# NM1120AE_v1 register map
File version: 1.0
Registers are 32-bit, read-write, reset 0x0 unless marked. A register's access mark holds for its fields unless they carry their own. Offsets are from the block's base; [hi:lo] are bit positions.

## SYS — SYS Register Map
Base 0x50000000
0x00 SYS_PDID ro reset not defined — Part Device Identification Number Register
  [31:0] PDID — Part Device Identification Number (Read Only). This register reflects device part number code. Software can read this register to identify which device is used.
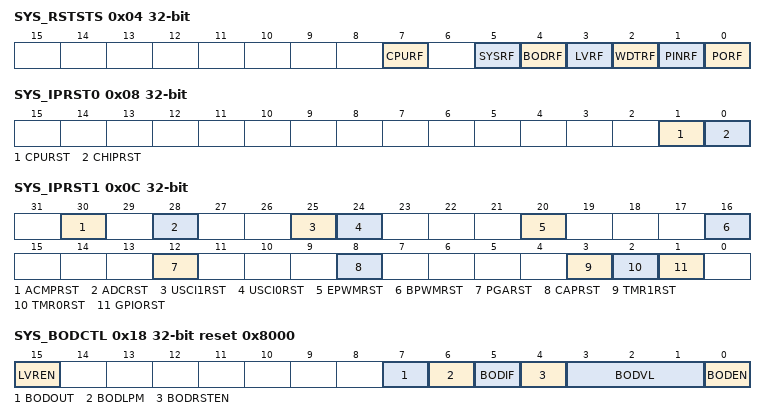
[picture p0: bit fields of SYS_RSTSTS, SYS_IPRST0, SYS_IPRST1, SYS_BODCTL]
0x04 SYS_RSTSTS (reset mask 0xFFFFFF00) — System Reset Status Register
  [7] CPURF — CPU Reset Flag. The CPU reset flag is set by hardware if software writes CPURST (SYS_IPRST0[1]) 1 to reset Cortex-M0 Core and Flash Memory Controller (FMC). Note: Write 1 to clear this bit to 0.
    0=No reset from CPU; 1=The Cortex-M0 Core and FMC are reset by software setting CPURST to 1
  [5] SYSRF — System Reset Flag. The system reset flag is set by the "Reset Signal" from the Cortex-M0 Core to indicate the previous reset source. Note: Write 1 to clear this bit to 0.
    0=No reset from Cortex-M0; 1=The Cortex-M0 had issued the reset signal to reset the system by writing 1 to the bit SYSRESETREQ(AIRCR[2], Application Interrupt and Reset Control Register, address = 0xE000ED0C) in system control registers of Cortex-M0 core
  [4] BODRF — BOD Reset Flag. The BOD reset flag is set by the "Reset Signal" from the Brown-Out Detector to indicate the previous reset source. Note: Write 1 to clear this bit to 0.
    0=No reset from BOD; 1=The BOD had issued the reset signal to reset the system
  [3] LVRF — LVR Reset Flag. The LVR reset flag is set by the "Reset Signal" from the Low Voltage Reset Controller to indicate the previous reset source. Note: Write 1 to clear this bit to 0.
    0=No reset from LVR; 1=LVR controller had issued the reset signal to reset the system
  [2] WDTRF — WDT Reset Flag. The WDT reset flag is set by the "Reset Signal" from the Watchdog Timer or Window Watchdog Timer to indicate the previous reset source. Note1: Write 1 to clear this bit to 0. Note2: Watchdog Timer register RSTF(WDT_CTL[2]) bit is set if the system has been reset by WDT time-out reset. Window Watchdog Timer register WWDTRF(WWDT_STATUS[1]) bit is set if the system has been reset by WWDT time-out reset.
    0=No reset from watchdog timer or window watchdog timer; 1=The watchdog timer or window watchdog timer had issued the reset signal to reset the system
  [1] PINRF — NRESET Pin Reset Flag. The nRESET pin reset flag is set by the "Reset Signal" from the nRESET Pin to indicate the previous reset source. Note: Write 1 to clear this bit to 0.
    0=No reset from nRESET pin; 1=Pin nRESET had issued the reset signal to reset the system
  [0] PORF — POR Reset Flag. The POR reset flag is set by the "Reset Signal" from the Power-on Reset (POR) Controller or bit CHIPRST (SYS_IPRST0[0]) to indicate the previous reset source. Note: Write 1 to clear this bit to 0.
    0=No reset from POR or CHIPRST; 1=Power-on Reset (POR) or CHIPRST had issued the reset signal to reset the system
0x08 SYS_IPRST0 — Peripheral Reset Control Register 0
  [1] CPURST — Processor Core One-shot Reset (Write Protect). Setting this bit will only reset the processor core and Flash Memory Controller(FMC), and this bit will automatically return to 0 after the 2 clock cycles. Note: This bit is write protected. Refer to the SYS_REGLCTL register.
    0=Processor core normal operation; 1=Processor core one-shot reset
  [0] CHIPRST — Chip One-shot Reset (Write Protect). Setting this bit will reset the whole chip, including Processor core and all peripherals, and this bit will automatically return to 0 after the 2 clock cycles. The CHIPRST is same as the POR reset, all the chip controllers is reset and the chip setting from flash are also reload. About the difference between CHIPRST and SYSRESETREQ(AIRCR[2]), please refer to section 6.2.2. Note: This bit is write protected. Refer to the SYS_REGLCTL register.
    0=Chip normal operation; 1=Chip one-shot reset
0x0C SYS_IPRST1 — Peripheral Reset Control Register 1
  [30] ACMPRST — ACMP Controller Reset
    0=ACMP controller normal operation; 1=ACMP controller reset
  [28] ADCRST — ADC Controller Reset
    0=ADC controller normal operation; 1=ADC controller reset
  [25] USCI1RST — USCI1 Controller Reset
    0=USCI1 controller normal operation; 1=USCI1 controller reset
  [24] USCI0RST — USCI0 Controller Reset
    0=USCI0 controller normal operation; 1=USCI0 controller reset
  [20] EPWMRST — Enhanced PWM Controller Reset
    0=EPWM controller normal operation; 1=EPWM controller reset
  [16] BPWMRST — Basic PWM Controller Reset
    0=BPWM controller normal operation; 1=BPWM controller reset
  [12] PGARST — PGA Controller Reset
    0=PGA controller normal operation; 1=PGA controller reset
  [8] CAPRST — CAP Controller Reset
    0=CAP controller normal operation; 1=CAP controller reset
  [3] TMR1RST — Timer1 Controller Reset
    0=Timer1 controller normal operation; 1=Timer1 controller reset
  [2] TMR0RST — Timer0 Controller Reset
    0=Timer0 controller normal operation; 1=Timer0 controller reset
  [1] GPIORST — GPIO Controller Reset
    0=GPIO controller normal operation; 1=GPIO controller reset
0x10 SYS_WAIT reset 0x1 — HCLK Wait State Cycle Control Register
  [0] HCLKWS — HCLK Wait State Cycle Control Bit. This bit is used to enable/disable HCLK wait state when access Flash. Note: When HCLK frequency is faster than 48MHz, insert one wait state is necessary.
    0=No wait state; 1=One wait state inserted when CPU access Flash
0x18 SYS_BODCTL reset 0x8000 (reset mask 0xFFFFFF00) — Brown-Out Detector Control Register
  [15] LVREN — Low Voltage Reset Enable Control (Write Protect). The LVR function resets the chip when the input power voltage is lower than LVR circuit setting. LVR function is enabled by default. Note: This bit is write protected. Refer to the SYS_REGLCTL register.
    0=Low Voltage Reset function Disabled; 1=Low Voltage Reset function Enabled
  [7] BODOUT — Brown-out Detector Output Status
    0=Brown-out Detector output status is 0. It means the detected voltage is higher than BODVL setting or BODEN is 0; 1=Brown-out Detector output status is 1. It means the detected voltage is lower than BODVL setting. If the BODEN is 0, BOD function disabled , this bit always responds 0000
  [6] BODLPM — Brown-out Detector Low Power Mode (Write Protect). Note1: The BOD consumes about 100uA in normal mode, the low power mode can reduce the current to about 1/10 but slow the BOD response. Note2: This bit is write protected. Refer to the SYS_REGLCTL register.
    0=BOD operate in normal mode (default); 1=BOD Low Power mode Enabled
  [5] BODIF — Brown-out Detector Interrupt Flag. Note: Write 1 to clear this bit to 0.
    0=Brown-out Detector does not detect any voltage draft at VDD down through or up through the voltage of BODVL setting; 1=When Brown-out Detector detects the VDD is dropped down through the voltage of BODVL setting or the VDD is raised up through the voltage of BODVL setting, this bit is set to 1 and the brown-out interrupt is requested if brown-out interrupt is enabled
  [4] BODRSTEN — Brown-out Reset Enable Control (Write Protect). The default value is set by flash controller user configuration register CBORST(CONFIG0[19]) bit . Note1: While the Brown-out Detector function is enabled (BODEN high) and BOD reset function is enabled (BODRSTEN high), BOD will assert a signal to reset chip when the detected voltage is lower than the threshold (BODOUT high). While the BOD function is enabled (BODEN high) and BOD interrupt function is enabled (BODRSTEN low), BOD will assert an interrupt if BODOUT is high. BOD interrupt will keep till to the BODEN set to 0. BOD interrupt can be blocked by disabling the NVIC BOD interrupt or disabling BOD function (set BODEN low). BOD will wake CPU up when BODOUT is high in power-down mode. Note2: This bit is write protected. Refer to the SYS_REGLCTL register.
    0=Brown-out "INTERRUPT" function Enabled; 1=Brown-out "RESET" function Enabled
  [3:1] BODVL — Brown-out Detector Threshold Voltage Selection (Write Protect). The default value is set by flash controller user configuration register CBOV (CONFIG0 [22:20]). Note: This bit is write protected. Refer to the SYS_REGLCTL register.
    0=Brown-Out Detector threshold voltage is 2.0V; 1=Brown-Out Detector threshold voltage is 2.2V; 2=Brown-Out Detector threshold voltage is 2.4V; 3=Brown-Out Detector threshold voltage is 2.7V; 4=Brown-Out Detector threshold voltage is 3.0V; 5=Brown-Out Detector threshold voltage is 3.7V; 6=Brown-Out Detector threshold voltage is 4.0V; 7=Brown-Out Detector threshold voltage is 4.3V
  [0] BODEN — Brown-out Detector Enable Control (Write Protect). The default value is set by flash controller user configuration register CBODEN (CONFIG0 [18]). Note: This bit is write protected. Refer to the SYS_REGLCTL register.
    0=Brown-out Detector function Disabled; 1=Brown-out Detector function Enabled
0x1C SYS_IVSCTL — Internal Voltage Source Control Register
  [0] VTEMPEN — Temperature Sensor Enable Control. This bit is used to enable/disable temperature sensor function. Note: After this bit is set to 1, the value of temperature sensor output can be obtained from A/D conversion result. Please refer to ADC function chapter for details.
    0=Temperature sensor function Disabled (default); 1=Temperature sensor function Enabled
0x24 SYS_PORCTL (reset mask 0xFFFFFF00) — Power-On-Reset Controller Register
  [15:0] POROFF — Power-on Reset Enable Control (Write Protect). When powered on, the POR circuit generates a reset signal to reset the whole chip function, but noise on the power may cause the POR active again. User can disable internal POR circuit to avoid unpredictable noise to cause chip reset by writing 0x5AA5 to this field. The POR function will be active again when this field is set to another value or chip is reset by other reset source, including: nRESET, Watchdog, LVR reset, BOD reset, ICE reset command and the software-chip reset function. Note: This bit is write protected. Refer to the SYS_REGLCTL register.
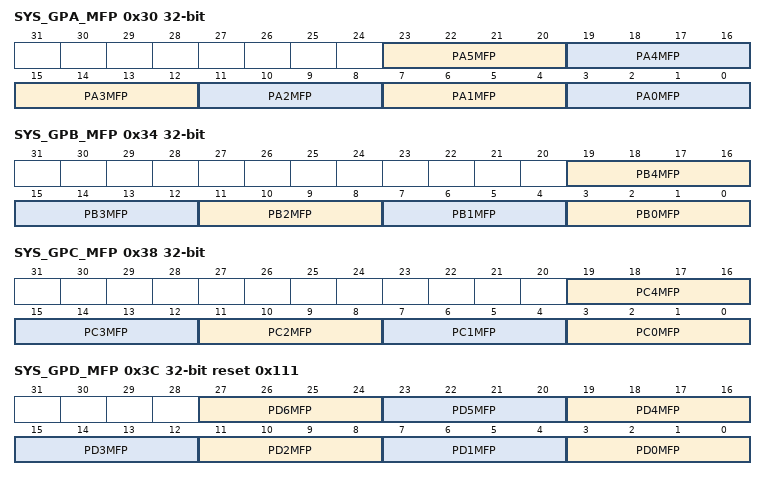
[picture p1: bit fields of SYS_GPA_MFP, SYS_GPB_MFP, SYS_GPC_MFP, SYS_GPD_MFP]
0x30 SYS_GPA_MFP — GPIOA Multiple Function Control Register
  [23:20] PA5MFP — PA.5 Multi-function Pin Selection
  [19:16] PA4MFP — PA.4 Multi-function Pin Selection
  [15:12] PA3MFP — PA.3 Multi-function Pin Selection
  [11:8] PA2MFP — PA.2 Multi-function Pin Selection
  [7:4] PA1MFP — PA.1 Multi-function Pin Selection
  [3:0] PA0MFP — PA.0 Multi-function Pin Selection
0x34 SYS_GPB_MFP — GPIOB Multiple Function Control Register
  [19:16] PB4MFP — PB.4 Multi-function Pin Selection
  [15:12] PB3MFP — PB.3 Multi-function Pin Selection
  [11:8] PB2MFP — PB.2 Multi-function Pin Selection
  [7:4] PB1MFP — PB.1 Multi-function Pin Selection
  [3:0] PB0MFP — PB.0 Multi-function Pin Selection
0x38 SYS_GPC_MFP — GPIOC Multiple Function Control Register
  [19:16] PC4MFP — PC.4 Multi-function Pin Selection
  [15:12] PC3MFP — PC.3 Multi-function Pin Selection
  [11:8] PC2MFP — PC.2 Multi-function Pin Selection
  [7:4] PC1MFP — PC.1 Multi-function Pin Selection
  [3:0] PC0MFP — PC.0 Multi-function Pin Selection
0x3C SYS_GPD_MFP reset 0x111 — GPIOD Multiple Function Control Register
  [27:24] PD6MFP — PD.6 Multi-function Pin Selection
  [23:20] PD5MFP — PD.5 Multi-function Pin Selection
  [19:16] PD4MFP — PD.4 Multi-function Pin Selection
  [15:12] PD3MFP — PD.3 Multi-function Pin Selection
  [11:8] PD2MFP — PD.2 Multi-function Pin Selection
  [7:4] PD1MFP — PD.1 Multi-function Pin Selection
  [3:0] PD0MFP — PD.0 Multi-function Pin Selection
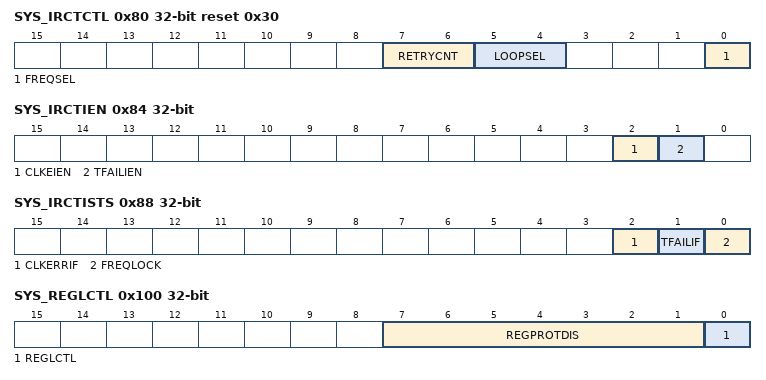
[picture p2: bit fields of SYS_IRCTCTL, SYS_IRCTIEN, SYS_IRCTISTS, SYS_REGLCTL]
0x80 SYS_IRCTCTL reset 0x30 — HIRC Trim Control Register
  [7:6] RETRYCNT — Trim Value Update Limitation Count. This field defines that how many times the auto trim circuit will try to update the HIRC trim value before the frequency of HIRC locked. Once the HIRC locked, the internal trim value update counter will be reset. If the trim value update counter reached this limitation value and frequency of HIRC still doesn't lock, the auto trim operation will be disabled and FREQSEL will be cleared to 00.
    0=Trim retry count limitation is 64 loops; 1=Trim retry count limitation is 128 loops; 2=Trim retry count limitation is 256 loops; 3=Trim retry count limitation is 512 loops
  [5:4] LOOPSEL — Trim Calculation Loop Selection. This field defines that trim value calculation is based on how many 32.768 kHz clock. Note: For example, if LOOPSEL is set as 00, auto trim circuit will calculate trim value based on the average frequency difference in 4 32.768 kHz clock.
    0=Trim value calculation is based on average difference in 4 32.768 kHz clock; 1=Trim value calculation is based on average difference in 8 32.768 kHz clock; 2=Trim value calculation is based on average difference in 16 32.768 kHz clock; 3=Trim value calculation is based on average difference in 32 32.768 kHz clock
  [0] FREQSEL — Trim Frequency Selection. This field indicates the target frequency of 48 MHz internal high speed RC oscillator (HIRC) auto trim.
    0=HIRC auto trim function Disabled; 1=HIRC auto trim function and trim HIRC to 48 MHz Enabled
0x84 SYS_IRCTIEN — HIRC Trim Interrupt Enable Register
  [2] CLKEIEN — Clock Error Interrupt Enable Control. This bit controls if CPU would get an interrupt while clock is inaccuracy during auto trim operation. If this bit is set to1, and CLKERRIF(SYS_IRCTSTS[2]) is set during auto trim operation, an interrupt will be triggered to notify the clock frequency is inaccuracy.
    0=CLKERRIF(SYS_IRCTSTS[2]) status to trigger an interrupt to CPU Disabled; 1=CLKERRIF(SYS_IRCTSTS[2]) status to trigger an interrupt to CPU Enabled
  [1] TFAILIEN — Trim Failure Interrupt Enable Control. This bit controls if an interrupt will be triggered while HIRC trim value update limitation count reached and HIRC frequency still not locked on target frequency set by FREQSEL(SYS_IRCTCTL[1:0]). If this bit is high and TFAILIF(SYS_IRCTSTS[1]) is set during auto trim operation, an interrupt will be triggered to notify that HIRC trim value update limitation count was reached.
    0=TFAILIF(SYS_IRCTSTS[1]) status to trigger an interrupt to CPU Disabled; 1=TFAILIF(SYS_IRCTSTS[1]) status to trigger an interrupt to CPU Enabled
0x88 SYS_IRCTISTS — HIRC Trim Interrupt Status Register
  [2] CLKERRIF — Clock Error Interrupt Status. When the frequency of 32.768 kHz external low speed crystal oscillator (LXT) or 48 MHz internal high speed RC oscillator (HIRC) is shift larger to unreasonable value, this bit will be set and to be an indicate that clock frequency is inaccuracy. If this bit is set and CLKEIEN(SYS_IRCTIEN[2]) is high, an interrupt will be triggered to notify the clock frequency is inaccuracy. Write 1 to clear this to 0.
    0=Clock frequency is accuracy; 1=Clock frequency is inaccuracy
  [1] TFAILIF — Trim Failure Interrupt Status. This bit indicates that HIRC trim value update limitation count reached and the HIRC clock frequency still doesn't be locked. Once this bit is set, the auto trim operation stopped and FREQSEL(SYS_iRCTCTL[1:0]) will be cleared to 00 by hardware automatically. If this bit is set and TFAILIEN(SYS_IRCTIEN[1]) is high, an interrupt will be triggered to notify that HIRC trim value update limitation count was reached. Write 1 to clear this to 0.
    0=Trim value update limitation count does not reach; 1=Trim value update limitation count reached and HIRC frequency still not locked
  [0] FREQLOCK — HIRC Frequency Lock Status. This bit indicates the HIRC frequency is locked. This is a status bit and doesn't trigger any interrupt.
    0=The internal high-speed oscillator frequency doesn't lock at 48 MHz yet; 1=The internal high-speed oscillator frequency locked at 48 MHz
0x100 SYS_REGLCTL — Register Write-Protection Control Register
  [7:1] REGPROTDIS wo — Register Write-protection Code (Write Only). Some registers have write-protection function. Writing these registers have to disable the protected function by writing the sequence value 0x59, 0x16, 0x88 to this field. After this sequence is completed, the SYS_REGLCTL bit will be set to 1 and write-protection registers can be normal write.
  [0] REGLCTL ro — Register Lock Control Disable Index (Read Only) . The Protected registers are: SYS_IPRST0. SYS_IPRST0. SYS_BODCTL. LDOCR. SYS_PORCTL. CLK_PWRCTL. CLK_APBCLK bit[0]. CLK_CLKSEL0. CLK_CLKSEL1 bit[1:0]. NMI_SEL bit[8]. FMC_ISPCTL. FMC_ISPTRG. WDT_CTL. Note: The bits which are write-protected will be noted as" (Write Protect)" beside the description.
    0=Write-protection Enabled for writing protected registers. Any write to the protected register is ignored; 1=Write-protection Disabled for writing protected registers
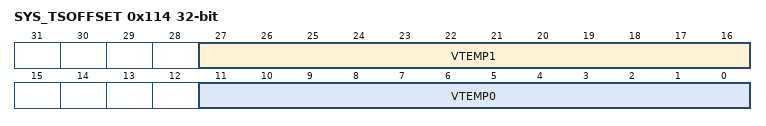
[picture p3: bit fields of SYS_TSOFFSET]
0x114 SYS_TSOFFSET ro (reset mask 0xF000F000) — Temperature sensor offset Register
  [27:16] VTEMP1 — Temperature Sensor Offset Value. This field reflects temperature sensor output voltage offset at 125oC.
  [11:0] VTEMP0 — Temperature Sensor Offset Value. This field reflects temperature sensor output voltage offset at 25oC.
